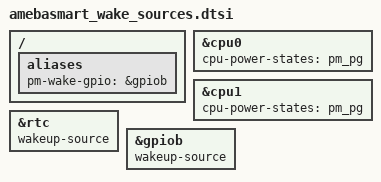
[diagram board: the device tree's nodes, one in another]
/*
 * Copyright (c) 2026 Realtek Semiconductor Corp.
 *
 * SPDX-License-Identifier: Apache-2.0
 *
 * AmebaSmart (RTL8730E) wake sources and idle states for the PM tests, shared
 * by every board target of this SoC. A board overlay replaces app.overlay
 * rather than merging with it, so the per-target overlays include this instead
 * of relying on one.
 *
 * TIMER0 is the counter wake source here, unlike on the Cortex-M SoCs: it is
 * the only low-speed basic timer carrying a wakeup-source-id on this SoC, and
 * the reason to avoid it there does not apply -- the Zephyr system timer on the
 * CA32 is the ARM generic timer, not TIM0/SYSTIMER, so driving TIM0 through the
 * counter API does not disturb the kernel clock.
 */

/*
 * Unlike the rtl8721f_evb / rtl872xda_evb board DTS files, rtl8730e_evb.dts
 * declares no cpu-power-states, so the states have to be attached here. CPU1
 * must declare them too: without them its pm_policy returns NULL, it never
 * parks or hotplugs off, and CPU0 hot-spins waiting for it instead of
 * cluster-power-gating.
 *
 * Suspend-to-RAM only, deliberately. Clock-gating is offered by the SoC's
 * devicetree but does not come back on this SoC -- the NP takes a SecureFault
 * (attribution unit violation) while the AP is gated -- and the residency policy
 * would pick it for any idle window between 5.0 and 7.5 ms, taking the run down
 * at a point unrelated to whatever case was executing.
 */
&cpu0 {
	cpu-power-states = <&pm_pg>;
};

&cpu1 {
	cpu-power-states = <&pm_pg>;
};

/ {
	/*
	 * No pm-wake-counter here. TIMER0 is TIM0, the always-on reference the PM
	 * tick recovery reads, and on this SoC it is also the only basic timer with a
	 * wakeup-source-id -- the two uses are mutually exclusive, and the reference
	 * wins: handing the node to the counter driver reprograms and stops it (the
	 * hal's CA32 PM code likewise keeps TIM0 to itself and wakes from rtc/gpio).
	 * The cases that need an armable wake source use the rtc instead.
	 */
	aliases {
		pm-wake-gpio = &gpiob;
	};
};

&rtc {
	status = "okay";
	wakeup-source;
};

&gpiob {
	status = "okay";
	wakeup-source;
};
